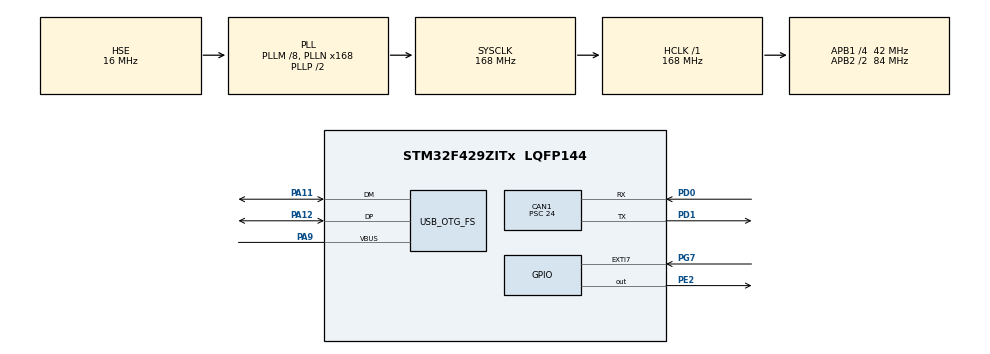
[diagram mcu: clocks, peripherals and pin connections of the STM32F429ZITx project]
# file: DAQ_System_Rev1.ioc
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CAN1.BS1=CAN_BS1_3TQ
CAN1.BS2=CAN_BS2_3TQ
CAN1.CalculateBaudRate=250000
CAN1.CalculateTimeBit=4000
CAN1.CalculateTimeQuantum=571.4285714285714
CAN1.Prescaler=24
FATFS._FS_EXFAT=1
FATFS._MAX_SS=4096
FATFS._USE_LFN=2
FREERTOS.Tasks01=defaultTask,24,128,StartDefaultTask,Default,NULL,Dynamic,NULL,NULL
Mcu.Family=STM32F4
Mcu.Name=STM32F429ZITx
Mcu.Package=LQFP144
NVIC.CAN1_RX0_IRQn=true\:5\:0\:false\:false\:true\:true\:true\:true\:true
NVIC.CAN1_RX1_IRQn=true\:5\:0\:false\:false\:true\:true\:true\:true\:true
NVIC.EXTI9_5_IRQn=true\:5\:0\:false\:false\:true\:true\:true\:true\:true
NVIC.OTG_FS_IRQn=true\:15\:0\:true\:false\:true\:true\:false\:true\:true
NVIC.PriorityGroup=NVIC_PRIORITYGROUP_4
NVIC.TIM6_DAC_IRQn=true\:15\:0\:false\:false\:true\:false\:false\:true\:true
NVIC.TIM7_IRQn=true\:5\:0\:false\:false\:true\:true\:true\:true\:true
NVIC.TimeBase=TIM6_DAC_IRQn
NVIC.TimeBaseIP=TIM6
PA11.Mode=Host_Only
PA11.Signal=USB_OTG_FS_DM
PA12.Mode=Host_Only
PA12.Signal=USB_OTG_FS_DP
PA9.Mode=Activate_VBUS
PA9.Signal=USB_OTG_FS_VBUS
PC14/OSC32_IN.Mode=LSE-External-Clock-Source
PC14/OSC32_IN.Signal=RCC_OSC32_IN
PC15/OSC32_OUT.Mode=LSE-External-Clock-Source
PC15/OSC32_OUT.Signal=RCC_OSC32_OUT
PD0.Mode=CAN_Activate
PD0.Signal=CAN1_RX
PD1.Mode=CAN_Activate
PD1.Signal=CAN1_TX
PE2.Signal=GPIO_Output
PG7.GPIO_ModeDefaultEXTI=GPIO_MODE_IT_RISING_FALLING
PG7.Signal=GPXTI7
PH0/OSC_IN.Mode=HSE-External-Oscillator
PH0/OSC_IN.Signal=RCC_OSC_IN
PH1/OSC_OUT.Mode=HSE-External-Oscillator
PH1/OSC_OUT.Signal=RCC_OSC_OUT
ProjectManager.HeapSize=0x200
ProjectManager.StackSize=0x400
ProjectManager.TargetToolchain=STM32CubeIDE
RCC.48MHZClocksFreq_Value=48000000
RCC.AHBFreq_Value=168000000
RCC.APB1CLKDivider=RCC_HCLK_DIV4
RCC.APB1Freq_Value=42000000
RCC.APB1TimFreq_Value=84000000
RCC.APB2CLKDivider=RCC_HCLK_DIV2
RCC.APB2Freq_Value=84000000
RCC.APB2TimFreq_Value=168000000
RCC.CortexFreq_Value=168000000
RCC.HCLKFreq_Value=168000000
RCC.HSE_VALUE=16000000
RCC.HSI_VALUE=16000000
RCC.LSE_VALUE=32768
RCC.PLLM=8
RCC.PLLN=168
RCC.PLLQ=7
RCC.SYSCLKFreq_VALUE=168000000
RCC.SYSCLKSource=RCC_SYSCLKSOURCE_PLLCLK
RCC.VCOOutputFreq_Value=336000000
TIM7.Period=21000-1
TIM7.Prescaler=8000-1
USB_HOST.USBH_HandleTypeDef-MSC_FS=hUsbHostFS
USB_HOST.USBH_PROCESS_PRIO-MSC_FS=osPriorityNormal
USB_HOST.USBH_PROCESS_STACK_SIZE-MSC_FS=1024
USB_HOST.VirtualModeFS=Msc
USB_OTG_FS.VirtualMode=Host_Only
USB_OTG_FS.phy_itface=HCD_PHY_EMBEDDED
VP_FATFS_VS_USB.Mode=USB
VP_FREERTOS_VS_CMSIS_V2.Mode=CMSIS_V2
VP_SYS_VS_tim6.Mode=TIM6
VP_TIM7_VS_ClockSourceINT.Mode=Enable_Timer
VP_USB_HOST_VS_USB_HOST_MSC_FS.Mode=MSC_FS
board=custom

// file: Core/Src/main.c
/* USER CODE BEGIN Header */
/**
  ******************************************************************************
  * @file           : main.c
  * @brief          : Main program body
  ******************************************************************************
  * @attention
  *
  * Copyright (c) 2024 STMicroelectronics.
  * All rights reserved.
  *
  * This software is licensed under terms that can be found in the LICENSE file
  * in the root directory of this software component.
  * If no LICENSE file comes with this software, it is provided AS-IS.
  *
  ******************************************************************************
  */
/* USER CODE END Header */
#include "main.h"
#include "cmsis_os.h"
#include "can.h"
#include "fatfs.h"
#include "tim.h"
#include "usb_host.h"
#include "gpio.h"

/* USER CODE BEGIN Includes */
#include "../../Program/Src/app.hpp"
extern int to_unmount;
extern int to_log;

/* USER CODE END Includes */

/* USER CODE BEGIN PV */
extern uint32_t timestamp_thread_flag;
extern osThreadId_t timestampTaskHandle;

/* USER CODE END PV */

void SystemClock_Config(void);
void MX_FREERTOS_Init(void);

int main(void)
{

  /* MCU Configuration--------------------------------------------------------*/

  /* Reset of all peripherals, Initializes the Flash interface and the Systick. */
  HAL_Init();

  /* Configure the system clock */
  SystemClock_Config();

  /* Initialize all configured peripherals */
  MX_GPIO_Init();
  MX_FATFS_Init();
  MX_CAN1_Init();
  MX_TIM7_Init();
  /* USER CODE BEGIN 2 */
  cppMain();

  /* USER CODE END 2 */

  /* Init scheduler */
  osKernelInitialize();

  /* Call init function for freertos objects (in cmsis_os2.c) */
  MX_FREERTOS_Init();

  /* Start scheduler */
  osKernelStart();

  /* We should never get here as control is now taken by the scheduler */

  /* Infinite loop */
  while (1)
  {

  }
}

void SystemClock_Config(void)
{
  RCC_OscInitTypeDef RCC_OscInitStruct = {0};
  RCC_ClkInitTypeDef RCC_ClkInitStruct = {0};

  /** Configure the main internal regulator output voltage
  */
  __HAL_RCC_PWR_CLK_ENABLE();
  __HAL_PWR_VOLTAGESCALING_CONFIG(PWR_REGULATOR_VOLTAGE_SCALE1);

  /** Initializes the RCC Oscillators according to the specified parameters
  * in the RCC_OscInitTypeDef structure.
  */
  RCC_OscInitStruct.OscillatorType = RCC_OSCILLATORTYPE_HSE;
  RCC_OscInitStruct.HSEState = RCC_HSE_ON;
  RCC_OscInitStruct.PLL.PLLState = RCC_PLL_ON;
  RCC_OscInitStruct.PLL.PLLSource = RCC_PLLSOURCE_HSE;
  RCC_OscInitStruct.PLL.PLLM = 8;
  RCC_OscInitStruct.PLL.PLLN = 168;
  RCC_OscInitStruct.PLL.PLLP = RCC_PLLP_DIV2;
  RCC_OscInitStruct.PLL.PLLQ = 7;
  if (HAL_RCC_OscConfig(&RCC_OscInitStruct) != HAL_OK)
  {
    Error_Handler();
  }

  /** Initializes the CPU, AHB and APB buses clocks
  */
  RCC_ClkInitStruct.ClockType = RCC_CLOCKTYPE_HCLK|RCC_CLOCKTYPE_SYSCLK
                              |RCC_CLOCKTYPE_PCLK1|RCC_CLOCKTYPE_PCLK2;
  RCC_ClkInitStruct.SYSCLKSource = RCC_SYSCLKSOURCE_PLLCLK;
  RCC_ClkInitStruct.AHBCLKDivider = RCC_SYSCLK_DIV1;
  RCC_ClkInitStruct.APB1CLKDivider = RCC_HCLK_DIV4;
  RCC_ClkInitStruct.APB2CLKDivider = RCC_HCLK_DIV2;

  if (HAL_RCC_ClockConfig(&RCC_ClkInitStruct, FLASH_LATENCY_5) != HAL_OK)
  {
    Error_Handler();
  }
}

void HAL_TIM_PeriodElapsedCallback(TIM_HandleTypeDef *htim)
{
  /* USER CODE BEGIN Callback 0 */
	if (htim->Instance == TIM7) {
		osThreadFlagsSet(timestampTaskHandle, timestamp_thread_flag);
	}

  /* USER CODE END Callback 0 */
  if (htim->Instance == TIM6) {
    HAL_IncTick();
  }
}

void Error_Handler(void)
{
  __disable_irq();
  while (1)
  {
  }
}

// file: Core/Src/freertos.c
/* USER CODE BEGIN Header */
/**
  ******************************************************************************
  * File Name          : freertos.c
  * Description        : Code for freertos applications
  ******************************************************************************
  * @attention
  *
  * Copyright (c) 2024 STMicroelectronics.
  * All rights reserved.
  *
  * This software is licensed under terms that can be found in the LICENSE file
  * in the root directory of this software component.
  * If no LICENSE file comes with this software, it is provided AS-IS.
  *
  ******************************************************************************
  */
/* USER CODE END Header */

#include "FreeRTOS.h"
#include "task.h"
#include "main.h"
#include "cmsis_os.h"

/* Definitions for defaultTask */
osThreadId_t defaultTaskHandle;
const osThreadAttr_t defaultTask_attributes = {
  .name = "defaultTask",
  .stack_size = 128 * 4,
  .priority = (osPriority_t) osPriorityNormal,
};

void StartDefaultTask(void *argument);

extern void MX_USB_HOST_Init(void);
void MX_FREERTOS_Init(void); /* (MISRA C 2004 rule 8.1) */

void MX_FREERTOS_Init(void) {

  /* Create the thread(s) */
  /* creation of defaultTask */
  defaultTaskHandle = osThreadNew(StartDefaultTask, NULL, &defaultTask_attributes);

}

void StartDefaultTask(void *argument)
{
  /* init code for USB_HOST */
  MX_USB_HOST_Init();
  for(;;)
  {
    osDelay(1);
  }
}
